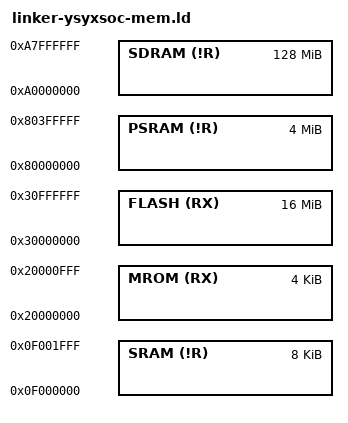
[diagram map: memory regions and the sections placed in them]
MEMORY {
  MROM (RX) : ORIGIN = 0x20000000, LENGTH = 4K
  FLASH (RX) : ORIGIN = 0x30000000, LENGTH = 16M
  SRAM (!R) : ORIGIN = 0x0f000000, LENGTH = 8K
  PSRAM (!R) : ORIGIN = 0x80000000, LENGTH = 4M
  SDRAM (!R) : ORIGIN = 0xa0000000, LENGTH = 128M
}

REGION_ALIAS("ROM", FLASH);
REGION_ALIAS("RAM", SDRAM);
REGION_ALIAS("FASTRAM", SRAM);
